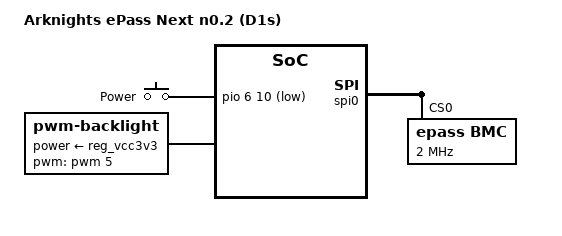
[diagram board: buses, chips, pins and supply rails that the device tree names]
// SPDX-License-Identifier: (GPL-2.0+ OR MIT)
/*
 * ePass Next revision n0.2.
 *
 * "n" is Next, as opposed to the prev-generation F1C boards whose revisions
 * are bare numbers (0.1 ... 0.6). U-Boot picks this tree out of dtbs.itb by
 * the device_rev it reads from the bootenv partition, so the name here and
 * the fdt-base-<rev> node in dtbs.its have to agree.
 *
 * Only what is wired differently from one board revision to the next belongs
 * here. Everything shared is in epass-next.dtsi, and the panel is a separate
 * overlay under screen/.
 */
/dts-v1/;

#include "epass-next.dtsi"
#include "ch32-touch-slider.dtsi"

/ {
	model = "Arknights ePass Next n0.2 (D1s)";

	keys {
		compatible = "gpio-keys";

		power {
			label = "Power";
			linux,code = <KEY_0>;
			/* gpiod owns both mux and pull to avoid a competing pinctrl claim. */
			gpios = <&pio 6 10 (GPIO_ACTIVE_LOW | GPIO_PULL_UP)>;
			debounce-interval = <20>;
		};
	};

	backlight: backlight {
		compatible = "pwm-backlight";
		/* LCD_PWM on PG4 */
		pwms = <&pwm 5 50000 0>;
		brightness-levels = <0 4 8 16 32 64 128 196 220 255>;
		default-brightness-level = <9>;
		power-supply = <&reg_vcc3v3>;
	};
};

&dsi {
	/*
	 * The revision owns the wiring -- which DSI channel the panel answers
	 * on, its reset line, what feeds it -- and the screen overlay fills in
	 * which panel it actually is by writing compatible and backlight onto
	 * this label. Same split as the F1C boards, where the st7701 init GPIOs
	 * sit in the revision dts and only the init sequence is in screen/.
	 *
	 * Without a compatible nothing binds, so a base tree booted with no
	 * screen overlay applied comes up headless rather than wrong.
	 */
	panel: panel@0 {
		reg = <0>;
		reset-gpios = <&pio 6 12 GPIO_ACTIVE_LOW>;
		iovcc-supply = <&reg_vcc3v3>;
		vcc-supply = <&reg_vcc3v3>;
	};
};

&spi0 {
	pinctrl-names = "default";
	pinctrl-0 = <&spi0_pins>;
	status = "okay";

	bmc@0 {
		compatible = "epass,bmc";
		reg = <0>;
		spi-max-frequency = <2000000>;
	};
};
